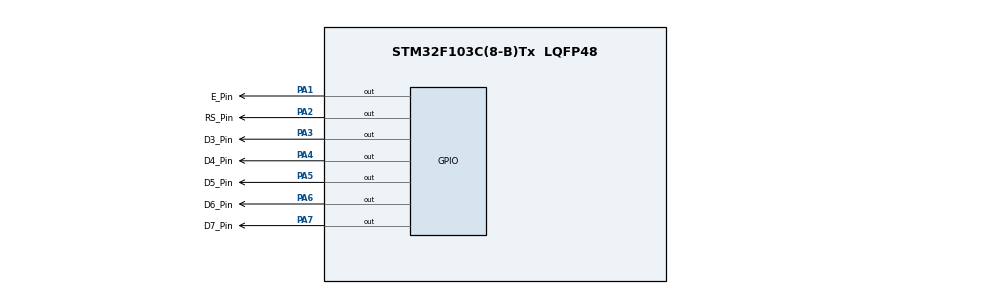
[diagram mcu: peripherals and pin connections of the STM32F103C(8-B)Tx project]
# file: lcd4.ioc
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Mcu.Family=STM32F1
Mcu.Name=STM32F103C(8-B)Tx
Mcu.Package=LQFP48
NVIC.PriorityGroup=NVIC_PRIORITYGROUP_4
PA1.GPIO_Label=E_Pin
PA1.Signal=GPIO_Output
PA13.Mode=Serial_Wire
PA13.Signal=SYS_JTMS-SWDIO
PA14.Mode=Serial_Wire
PA14.Signal=SYS_JTCK-SWCLK
PA2.GPIO_Label=RS_Pin
PA2.Signal=GPIO_Output
PA3.GPIO_Label=D3_Pin
PA3.Signal=GPIO_Output
PA4.GPIO_Label=D4_Pin
PA4.Signal=GPIO_Output
PA5.GPIO_Label=D5_Pin
PA5.Signal=GPIO_Output
PA6.GPIO_Label=D6_Pin
PA6.Signal=GPIO_Output
PA7.GPIO_Label=D7_Pin
PA7.Signal=GPIO_Output
PD0-OSC_IN.Mode=HSE-External-Oscillator
PD0-OSC_IN.Signal=RCC_OSC_IN
PD1-OSC_OUT.Mode=HSE-External-Oscillator
PD1-OSC_OUT.Signal=RCC_OSC_OUT
ProjectManager.HeapSize=0x200
ProjectManager.StackSize=0x400
ProjectManager.TargetToolchain=MDK-ARM V5.32
RCC.APB1Freq_Value=8000000
RCC.APB2Freq_Value=8000000
RCC.PLLSourceVirtual=RCC_PLLSOURCE_HSE
RCC.SYSCLKSource=RCC_SYSCLKSOURCE_HSE
RCC.USBFreq_Value=16000000
board=custom

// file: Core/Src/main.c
/* USER CODE BEGIN Header */
/**
  ******************************************************************************
  * @file           : main.c
  * @brief          : Main program body
  ******************************************************************************
  * @attention
  *
  * Copyright (c) 2023 STMicroelectronics.
  * All rights reserved.
  *
  * This software is licensed under terms that can be found in the LICENSE file
  * in the root directory of this software component.
  * If no LICENSE file comes with this software, it is provided AS-IS.
  *
  ******************************************************************************
  */
/* USER CODE END Header */
#include "main.h"
#include "lcd16x2.h"

void SystemClock_Config(void);
static void MX_GPIO_Init(void);

int main(void)
{

  /* MCU Configuration--------------------------------------------------------*/

  /* Reset of all peripherals, Initializes the Flash interface and the Systick. */
  HAL_Init();

  /* Configure the system clock */
  SystemClock_Config();

  /* Initialize all configured peripherals */
  MX_GPIO_Init();
	lcd16x2_init_4bits(RS_Pin_GPIO_Port, RS_Pin_Pin, E_Pin_Pin,
//      D0_GPIO_Port, D0_Pin, D1_Pin, D2_Pin, D3_Pin,
      D4_Pin_GPIO_Port, D4_Pin_Pin, D5_Pin_Pin, D6_Pin_Pin, D7_Pin_Pin);
	lcd16x2_1stLine();
  lcd16x2_printf("TurkMekatronik ");
	lcd16x2_2ndLine();
  lcd16x2_printf("Roket Takimi");
  HAL_Delay(3000);

  /* Infinite loop */
  /* USER CODE BEGIN WHILE */
	int i=10;
  while (1)
  {

		if(i >= 0)
		{
		lcd16x2_1stLine();
    lcd16x2_printf("%d",i);
    HAL_Delay(500);
		lcd16x2_clear();
		}
		else
		{
		lcd16x2_2ndLine();
    lcd16x2_printf("Atis");
    HAL_Delay(500);
		lcd16x2_clear();
			i=10;
		}

    /* USER CODE END WHILE */

    /* USER CODE BEGIN 3 */
		i--;
  }
  /* USER CODE END 3 */
}

void SystemClock_Config(void)
{
  RCC_OscInitTypeDef RCC_OscInitStruct = {0};
  RCC_ClkInitTypeDef RCC_ClkInitStruct = {0};

  /** Initializes the RCC Oscillators according to the specified parameters
  * in the RCC_OscInitTypeDef structure.
  */
  RCC_OscInitStruct.OscillatorType = RCC_OSCILLATORTYPE_HSE;
  RCC_OscInitStruct.HSEState = RCC_HSE_ON;
  RCC_OscInitStruct.PLL.PLLState = RCC_PLL_NONE;
  if (HAL_RCC_OscConfig(&RCC_OscInitStruct) != HAL_OK)
  {
    Error_Handler();
  }

  /** Initializes the CPU, AHB and APB buses clocks
  */
  RCC_ClkInitStruct.ClockType = RCC_CLOCKTYPE_HCLK|RCC_CLOCKTYPE_SYSCLK
                              |RCC_CLOCKTYPE_PCLK1|RCC_CLOCKTYPE_PCLK2;
  RCC_ClkInitStruct.SYSCLKSource = RCC_SYSCLKSOURCE_HSE;
  RCC_ClkInitStruct.AHBCLKDivider = RCC_SYSCLK_DIV1;
  RCC_ClkInitStruct.APB1CLKDivider = RCC_HCLK_DIV1;
  RCC_ClkInitStruct.APB2CLKDivider = RCC_HCLK_DIV1;

  if (HAL_RCC_ClockConfig(&RCC_ClkInitStruct, FLASH_LATENCY_0) != HAL_OK)
  {
    Error_Handler();
  }
}

static void MX_GPIO_Init(void)
{
  GPIO_InitTypeDef GPIO_InitStruct = {0};

  /* GPIO Ports Clock Enable */
  __HAL_RCC_GPIOD_CLK_ENABLE();
  __HAL_RCC_GPIOA_CLK_ENABLE();

  /*Configure GPIO pin Output Level */
  HAL_GPIO_WritePin(GPIOA, E_Pin_Pin|RS_Pin_Pin|D3_Pin_Pin|D4_Pin_Pin
                          |D5_Pin_Pin|D6_Pin_Pin|D7_Pin_Pin, GPIO_PIN_RESET);

  /*Configure GPIO pins : E_Pin_Pin RS_Pin_Pin D3_Pin_Pin D4_Pin_Pin
                           D5_Pin_Pin D6_Pin_Pin D7_Pin_Pin */
  GPIO_InitStruct.Pin = E_Pin_Pin|RS_Pin_Pin|D3_Pin_Pin|D4_Pin_Pin
                          |D5_Pin_Pin|D6_Pin_Pin|D7_Pin_Pin;
  GPIO_InitStruct.Mode = GPIO_MODE_OUTPUT_PP;
  GPIO_InitStruct.Pull = GPIO_NOPULL;
  GPIO_InitStruct.Speed = GPIO_SPEED_FREQ_LOW;
  HAL_GPIO_Init(GPIOA, &GPIO_InitStruct);

}

void Error_Handler(void)
{
  __disable_irq();
  while (1)
  {
  }
}
